# STM32WL5x_CM0P register map
File version: 1.5
CPU: CM0 r0p1, little endian, MPU, no FPU, 4 interrupt priority bits
Registers are 32-bit, read-write, reset 0x0 unless marked. A register's access mark holds for its fields unless they carry their own. Offsets are from the block's base; [hi:lo] are bit positions; {n}, {i} and the like mark numbered series; 'fields as' and 'values as' point back to an identical list.

## HSEM — Hardware semaphore
Base 0x58001400
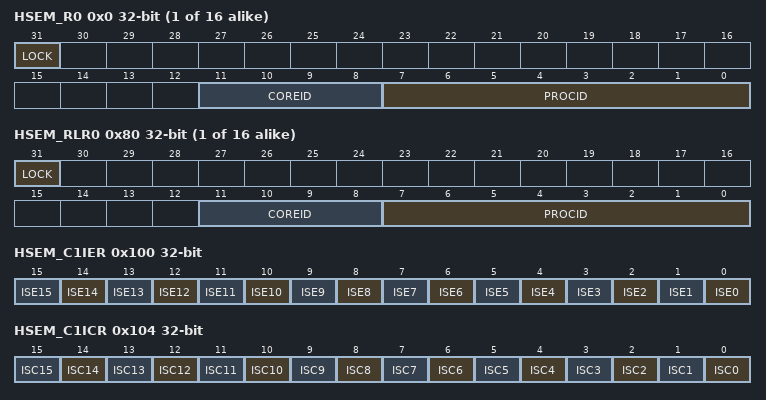
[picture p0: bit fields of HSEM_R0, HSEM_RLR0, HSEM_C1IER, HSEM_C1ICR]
{0x0+4i} HSEM_R{i} (i=0..15) — HSEM register HSEM_R0 HSEM_R31
  [31] LOCK — Lock indication
  [11:8] COREID
  [7:0] PROCID — Semaphore ProcessID
{0x80+4i} HSEM_RLR{i} ro (i=0..15) — HSEM Read lock register
  fields as HSEM_R0
0x100 HSEM_C1IER — HSEM Interrupt enable register
  [n] ISE{n} (n=0..15) — Interrupt semaphore n enable bit
0x104 HSEM_C1ICR ro — HSEM Interrupt clear register
  [n] ISC{n} (n=0..15) — Interrupt(N) semaphore n clear bit
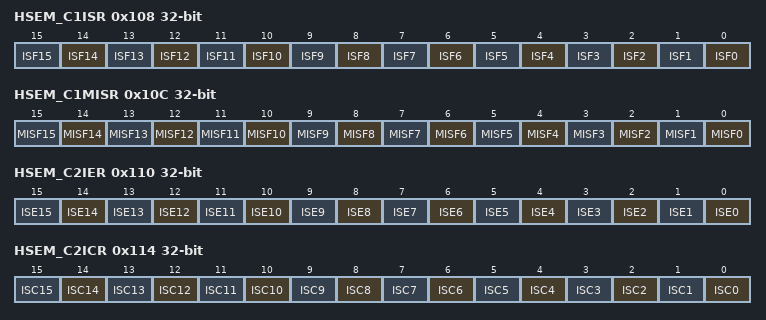
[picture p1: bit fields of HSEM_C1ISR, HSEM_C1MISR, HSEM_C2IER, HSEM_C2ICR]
0x108 HSEM_C1ISR ro — HSEM Interrupt status register
  [n] ISF{n} (n=0..15) — Interrupt(N) semaphore n status bit before enable (mask)
0x10C HSEM_C1MISR ro — HSEM Masked interrupt status register
  [n] MISF{n} (n=0..15) — masked interrupt(N) semaphore n status bit after enable (mask)
0x110 HSEM_C2IER — HSEM Interrupt enable register
  [n] ISE{n} (n=0..15) — Interrupt semaphore n enable bit
0x114 HSEM_C2ICR ro — HSEM Interrupt clear register
  [n] ISC{n} (n=0..15) — Interrupt(N) semaphore n clear bit
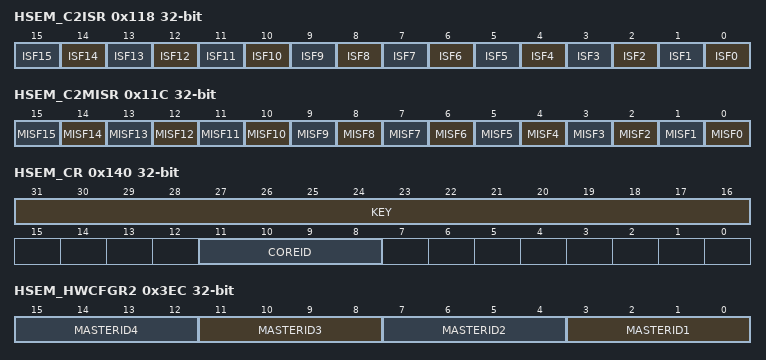
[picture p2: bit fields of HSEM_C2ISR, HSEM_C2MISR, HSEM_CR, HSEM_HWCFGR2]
0x118 HSEM_C2ISR ro — HSEM Interrupt status register
  fields as HSEM_C1ISR
0x11C HSEM_C2MISR ro — HSEM Masked interrupt status register
  fields as HSEM_C1MISR
0x140 HSEM_CR wo — HSEM Clear register
  [31:16] KEY — Semaphore clear Key
  [11:8] COREID
0x144 HSEM_KEYR — HSEM Interrupt clear register
  [31:16] KEY — Semaphore Clear Key
0x3EC HSEM_HWCFGR2 ro — HSEM config register
  [4n-1:4n-4] MASTERID{n} (n=1..4)
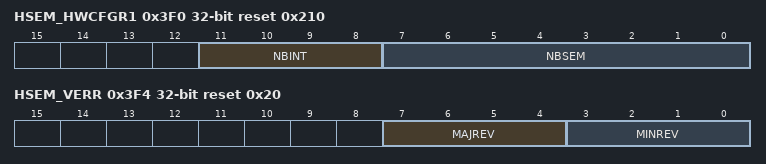
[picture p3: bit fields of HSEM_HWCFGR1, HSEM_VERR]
0x3F0 HSEM_HWCFGR1 ro reset 0x210 — HSEM config register
  [11:8] NBINT, [7:0] NBSEM
0x3F4 HSEM_VERR ro reset 0x20
  [7:4] MAJREV, [3:0] MINREV
0x3F8 HSEM_IPIDR ro reset 0x100072
  [31:0] IPID
0x3FC HSEM_SIDR ro reset 0xA3C5DD01
  [31:0] SID

## ADC — Analog to digital convertor
Base 0x40012400
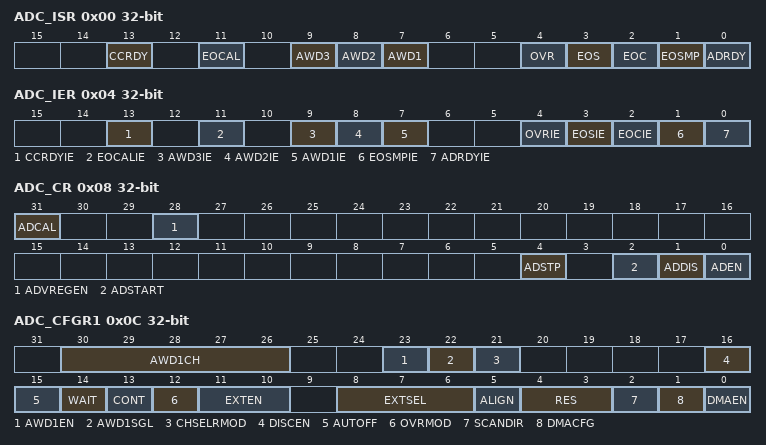
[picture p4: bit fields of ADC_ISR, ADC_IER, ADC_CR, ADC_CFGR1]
0x00 ADC_ISR — ADC interrupt and status register
  [13] CCRDY, [11] EOCAL, [9] AWD3, [8] AWD2, [7] AWD1, [4] OVR, [3] EOS, [2] EOC, [1] EOSMP, [0] ADRDY
0x04 ADC_IER — ADC interrupt enable register
  [13] CCRDYIE, [11] EOCALIE, [9] AWD3IE, [8] AWD2IE, [7] AWD1IE, [4] OVRIE, [3] EOSIE, [2] EOCIE, [1] EOSMPIE, [0] ADRDYIE
0x08 ADC_CR — ADC control register
  [31] ADCAL, [28] ADVREGEN, [4] ADSTP, [2] ADSTART, [1] ADDIS, [0] ADEN
0x0C ADC_CFGR1 — ADC configuration register 1
  [30:26] AWD1CH, [23] AWD1EN, [22] AWD1SGL, [21] CHSELRMOD, [16] DISCEN, [15] AUTOFF, [14] WAIT, [13] CONT, [12] OVRMOD, [11:10] EXTEN, [8:6] EXTSEL, [5] ALIGN, [4:3] RES, [2] SCANDIR, [1] DMACFG, [0] DMAEN
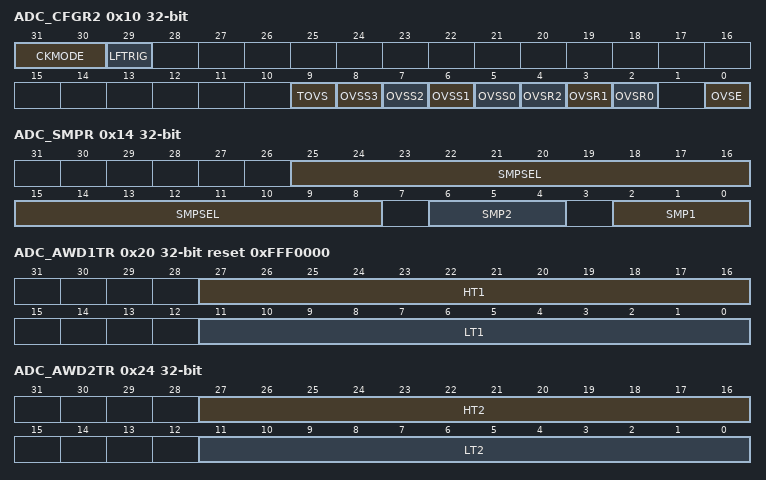
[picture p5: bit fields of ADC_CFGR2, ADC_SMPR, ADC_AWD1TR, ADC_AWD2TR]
0x10 ADC_CFGR2 — ADC configuration register 2
  [31:30] CKMODE, [29] LFTRIG, [9] TOVS, [n+5] OVSS{n} (n=0..3), [4] OVSR2, [3] OVSR1, [2] OVSR0, [0] OVSE
0x14 ADC_SMPR — ADC sampling time register
  [25:8] SMPSEL, [6:4] SMP2, [2:0] SMP1
0x20 ADC_AWD1TR reset 0xFFF0000 — ADC watchdog threshold register
  [27:16] HT1, [11:0] LT1
0x24 ADC_AWD2TR — ADC watchdog threshold register
  [27:16] HT2, [11:0] LT2
0x28 ADC_CHSELR0 — channel selection register
  [17:0] CHSEL
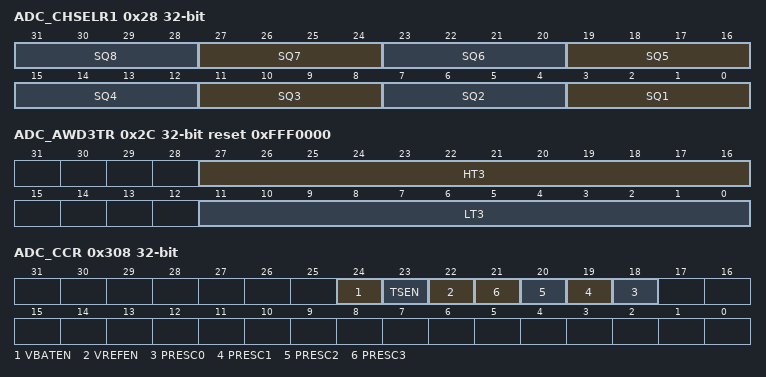
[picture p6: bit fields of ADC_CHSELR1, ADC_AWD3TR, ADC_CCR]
0x28 ADC_CHSELR1 (alternate view of ADC_CHSELR0) — channel selection register
  [4n-1:4n-4] SQ{n} (n=1..8)
0x2C ADC_AWD3TR reset 0xFFF0000 — ADC watchdog threshold register
  [27:16] HT3, [11:0] LT3
0x40 ADC_DR ro — ADC data register
  [15:0] DATA
0xA0 ADC_AWD2CR — ADC Analog Watchdog 2 Configuration register
  [17:0] AWD2CH
0xA4 ADC_AWD3CR — ADC Analog Watchdog 3 Configuration register
  [17:0] AWD3CH
0xB4 ADC_CALFACT — ADC Calibration factor
  [6:0] CALFACT
0x308 ADC_CCR — ADC common configuration register
  [24] VBATEN, [23] TSEN, [22] VREFEN, [n+18] PRESC{n} (n=0..3)

## IPCC — Inter Processor communication controller
Base 0x58000C00
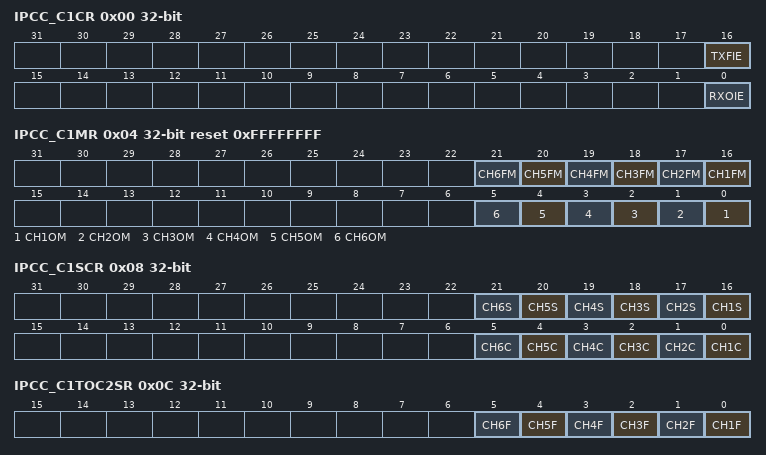
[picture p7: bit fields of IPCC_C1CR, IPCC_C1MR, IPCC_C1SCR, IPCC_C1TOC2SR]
0x00 IPCC_C1CR — IPCC Processor 1 control register
  [16] TXFIE, [0] RXOIE
0x04 IPCC_C1MR reset 0xFFFFFFFF — IPCC Processor 1 mask register
  [n+15] CH{n}FM (n=1..6), [n-1] CH{n}OM (n=1..6)
0x08 IPCC_C1SCR — Reading this register will always return 0x0000 0000.
  [n+15] CH{n}S (n=1..6), [n-1] CH{n}C (n=1..6)
0x0C IPCC_C1TOC2SR ro — IPCC processor 1 to processor 2 status register
  [n-1] CH{n}F (n=1..6)
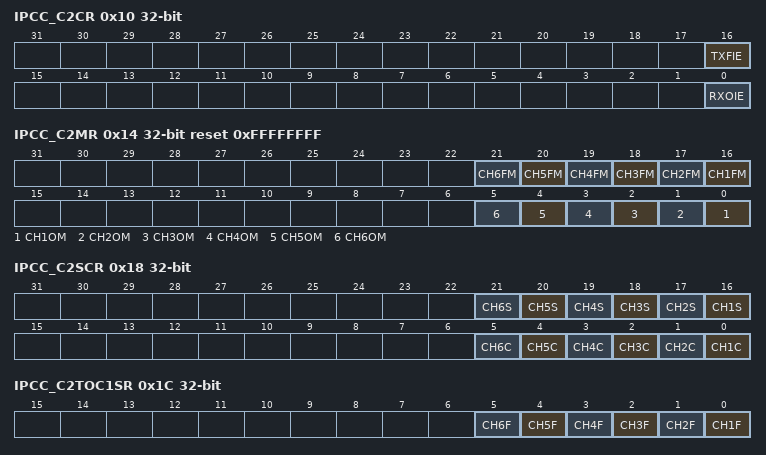
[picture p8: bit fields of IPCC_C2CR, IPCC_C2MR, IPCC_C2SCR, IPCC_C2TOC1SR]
0x10 IPCC_C2CR — IPCC Processor 2 control register
  [16] TXFIE, [0] RXOIE
0x14 IPCC_C2MR reset 0xFFFFFFFF — IPCC Processor 2 mask register
  [n+15] CH{n}FM (n=1..6), [n-1] CH{n}OM (n=1..6)
0x18 IPCC_C2SCR — Reading this register will always return 0x0000 0000.
  [n+15] CH{n}S (n=1..6), [n-1] CH{n}C (n=1..6)
0x1C IPCC_C2TOC1SR ro — IPCC processor 2 to processor 1 status register
  [n-1] CH{n}F (n=1..6)
0x3F0 IPCC_HWCFGR ro reset 0x6 — IPCC Hardware configuration register
  [7:0] CHANNELS
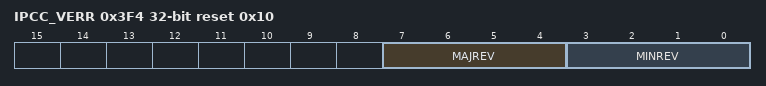
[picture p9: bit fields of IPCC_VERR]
0x3F4 IPCC_VERR ro reset 0x10 — IPCC IP Version register
  [7:4] MAJREV, [3:0] MINREV
0x3F8 IPCC_IPIDR ro reset 0x100071 — IPCC IP Identification register
  [31:0] ID
0x3FC IPCC_SIDR ro reset 0xA3C5DD01 — IPCC Size ID register
  [31:0] SID
